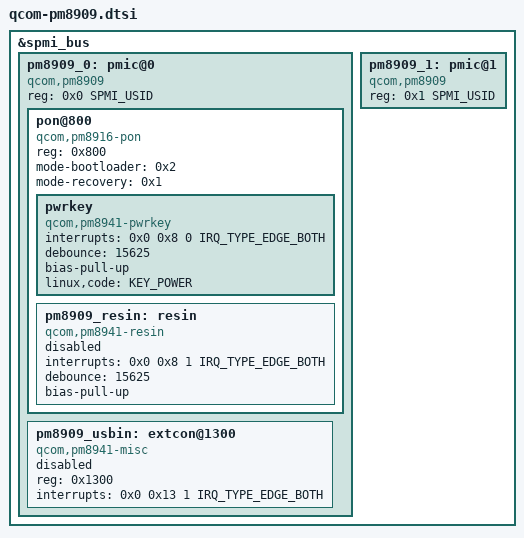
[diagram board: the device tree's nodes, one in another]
// SPDX-License-Identifier: GPL-2.0-only
#include <dt-bindings/input/linux-event-codes.h>
#include <dt-bindings/interrupt-controller/irq.h>
#include <dt-bindings/spmi/spmi.h>

&spmi_bus {
	pm8909_0: pmic@0 {
		compatible = "qcom,pm8909", "qcom,spmi-pmic";
		reg = <0x0 SPMI_USID>;
		#address-cells = <1>;
		#size-cells = <0>;

		pon@800 {
			compatible = "qcom,pm8916-pon";
			reg = <0x800>;
			mode-bootloader = <0x2>;
			mode-recovery = <0x1>;

			pwrkey {
				compatible = "qcom,pm8941-pwrkey";
				interrupts = <0x0 0x8 0 IRQ_TYPE_EDGE_BOTH>;
				debounce = <15625>;
				bias-pull-up;
				linux,code = <KEY_POWER>;
			};

			pm8909_resin: resin {
				compatible = "qcom,pm8941-resin";
				interrupts = <0x0 0x8 1 IRQ_TYPE_EDGE_BOTH>;
				debounce = <15625>;
				bias-pull-up;
				status = "disabled";
			};
		};

		pm8909_usbin: extcon@1300 {
			compatible = "qcom,pm8941-misc";
			reg = <0x1300>;
			interrupts = <0x0 0x13 1 IRQ_TYPE_EDGE_BOTH>;
			interrupt-names = "usb_vbus";
			status = "disabled";
		};
	};

	pm8909_1: pmic@1 {
		compatible = "qcom,pm8909", "qcom,spmi-pmic";
		reg = <0x1 SPMI_USID>;
		#address-cells = <1>;
		#size-cells = <0>;
	};
};
